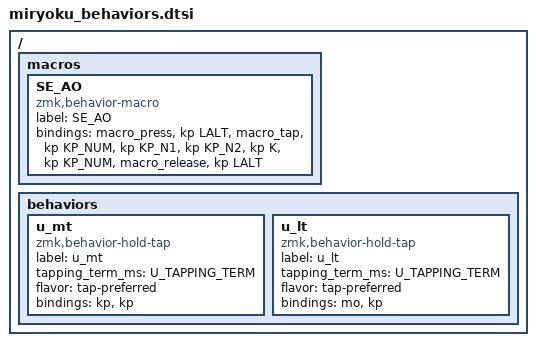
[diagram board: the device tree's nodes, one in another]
// Copyright 2022 Manna Harbour
// https://github.com/manna-harbour/miryoku

/ {
    macros {
        SE_AO: SE_AO {
            label = "SE_AO";
            compatible = "zmk,behavior-macro";
            #binding-cells = <0>;
            bindings
                = <&macro_press &kp LALT >
                , <&macro_tap &kp KP_NUM &kp KP_N1 &kp KP_N2 &kp K &kp KP_NUM>
                , <&macro_release &kp LALT>
                ;
        };
    };
  behaviors {
    u_mt: u_mt {
      compatible = "zmk,behavior-hold-tap";
      label = "u_mt";
      #binding-cells = <2>;
      tapping_term_ms = <U_TAPPING_TERM>;
      flavor = "tap-preferred";
      bindings = <&kp>, <&kp>;
    };
    u_lt: u_lt {
      compatible = "zmk,behavior-hold-tap";
      label = "u_lt";
      #binding-cells = <2>;
      tapping_term_ms = <U_TAPPING_TERM>;
      flavor = "tap-preferred";
      bindings = <&mo>, <&kp>;
    };
  };
};
